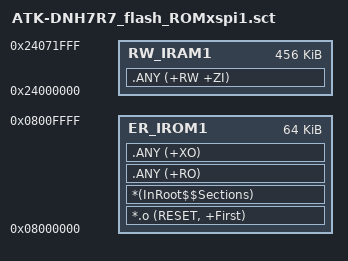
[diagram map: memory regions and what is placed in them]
LR_IROM1 0x08000000 0x00010000 {
    ER_IROM1 0x08000000 0x00010000 {
        *.o (RESET, +First)
        *(InRoot$$Sections)
		.ANY (+RO)
        .ANY (+XO)
    }
    RW_IRAM1 0x24000000 0x00072000 {
        .ANY (+RW +ZI)
    }
}
